# R7FA4E10D register map
Vendor: Renesas Electronics Corporation; Series: RA4E1; File version: 1.20.00
CPU: CM33 r0p4, little endian, MPU, FPU, VTOR, 4 interrupt priority bits, 96 interrupts
Registers are 8-bit, read-write, reset 0x0 unless marked. A register's access mark holds for its fields unless they carry their own. Offsets are from the block's base; [hi:lo] are bit positions.

## IIC0WU — Inter-Integrated Circuit 0 Wake-up Unit
Base 0x4009F014
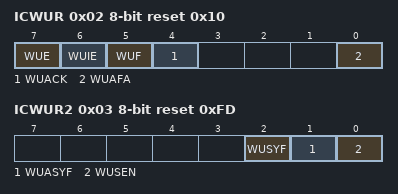
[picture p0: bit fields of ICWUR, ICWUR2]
0x02 ICWUR reset 0x10 — I2C Bus Wakeup Unit Register
  [7] WUE — Wakeup Function Enable
    0=Disable wakeup function; 1=Enable wakeup function
  [6] WUIE — Wakeup Interrupt Request Enable
    0=Disable wakeup interrupt request (IIC0_WUI); 1=Enable wakeup interrupt request (IIC0_WUI)
  [5] WUF — Wakeup Event Occurrence Flag
    0=Slave address not matching during wakeup; 1=Slave address matching during wakeup
  [4] WUACK — ACK Bit for Wakeup Mode
  [0] WUAFA — Wakeup Analog Filter Additional Selection
    0=Do not add the wakeup analog filter; 1=Add the wakeup analog filter
0x03 ICWUR2 reset 0xFD — I2C Bus Wakeup Unit Register 2
  [2] WUSYF ro — Wakeup Function Synchronous Operation Status Flag
    0=IIC asynchronous circuit enable condition; 1=IIC synchronous circuit enable condition
  [1] WUASYF ro — Wakeup Function Asynchronous Operation Status Flag
    0=IIC synchronous circuit enable condition; 1=IIC asynchronous circuit enable condition
  [0] WUSEN — Wakeup Function Synchronous Enable
    0=IIC asynchronous circuit enable; 1=IIC synchronous circuit enable

## CRC — Cyclic Redundancy Check Calculator
Base 0x40108000
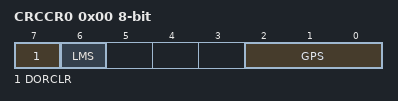
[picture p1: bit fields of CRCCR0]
0x00 CRCCR0 — CRC Control Register 0
  [7] DORCLR wo — CRCDOR/CRCDOR_HA/CRCDOR_BY Register Clear
    0=No effect; 1=Clear the CRCDOR/CRCDOR_HA/CRCDOR_BY register
  [6] LMS — CRC Calculation Switching
    0=Generate CRC code for LSB-first communication; 1=Generate CRC code for MSB-first communication
  [2:0] GPS — CRC Generating Polynomial Switching
    1=8-bit CRC-8 (X8 + X2 + X + 1); 2=16-bit CRC-16 (X16 + X15 + X2 + 1); 3=16-bit CRC-CCITT (X16 + X12 + X5 + 1); 4=32-bit CRC-32 (X32 + X26 + X23 + X22 + X16 + X12 + X11 +X10 + X8 + X7 + X5 + X4 + X2 + X + 1); 5=32-bit CRC-32C (X32 + X28 + X27 + X26 + X25 + X23 + X22 + X20 + X19 + X18 + X14 + X13 + X11 + X10 + X9 + X8 + X6 + 1); other=Others (No calculation is executed)
0x04 CRCDIR 32-bit — CRC Data Input Register
0x04 CRCDIR_BY (alternate view of CRCDIR) — CRC Data Input Register
0x08 CRCDOR 32-bit — CRC Data Output Register
0x08 CRCDOR_HA 16-bit (alternate view of CRCDOR) — CRC Data Output Register
0x08 CRCDOR_BY (alternate view of CRCDOR) — CRC Data Output Register

## DOC — Data Operation Circuit
Base 0x40109000
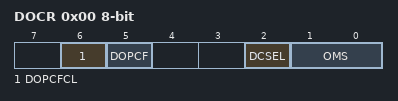
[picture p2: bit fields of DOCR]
0x00 DOCR — DOC Control Register
  [6] DOPCFCL — DOPCF Clear
    0=Retain DOPCF flag state; 1=Clear DOPCF flag
  [5] DOPCF ro — DOC Flag
  [2] DCSEL — Detection Condition Select
    0=Set DOPCF flag when data mismatch is detected; 1=Set DOPCF flag when data match is detected
  [1:0] OMS — Operating Mode Select
    0=Data comparison mode; 1=Data addition mode; 2=Data subtraction mode; 3=Setting prohibited
0x02 DODIR 16-bit — DOC Data Input Register
0x04 DODSR 16-bit — DOC Data Setting Register

## DAC12 — 12-bit D/A converter
Base 0x40171000
0x00 DADRn 16-bit — D/A Data Register n
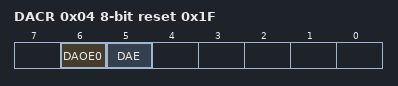
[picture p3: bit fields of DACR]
0x04 DACR reset 0x1F — D/A Control Register
  [6] DAOE0 — D/A Output Enable 0
    0=Disable D/A conversion and analog output of channel 0 (DA0); 1=Enable D/A conversion and analog output of channel 0 (DA0)
  [5] DAE — D/A Enable
    0=Control D/A conversion of channels 0 and 1 individually; 1=Control D/A conversion of channels 0 and 1 collectively
0x05 DADPR — DADR Format Select Register
  [7] DPSEL — DADR Format Select
    0=Right-justified format; 1=Left-justified format
0x06 DAADSCR — D/A A/D Synchronous Start Control Register
  [7] DAADST — D/A A/D Synchronous Conversion
    0=Do not synchronize DAC12 with ADC12 operation (disable interference reduction between D/A and A/D conversion); 1=Synchronize DAC12 with ADC12 operation (enable interference reduction between D/A and A/D conversion)
0x08 DAAMPCR — D/A Output Amplifier Control Register
  [6] DAAMP0 — Amplifier Control 0
    0=Do not use channel 0 output amplifier; 1=Use channel 0 output amplifier
0x1C DAASWCR — D/A Amplifier Stabilization Wait Control Register
  [6] DAASW0 — D/A Amplifier Stabilization Wait 0
    0=Amplifier stabilization wait off (output) for channel 0; 1=Amplifier stabilization wait on (high-Z) for channel 0
0x10C0 DAADUSR — D/A A/D Synchronous Unit Select Register
  [0] AMADSEL0 — A/D Unit 0 Select
    0=Do not select unit 0; 1=Select unit 0

## FLAD — Data Flash
Base 0x407FC000
0x40 FCKMHZ reset 0x3C — Data Flash Access Frequency Register
